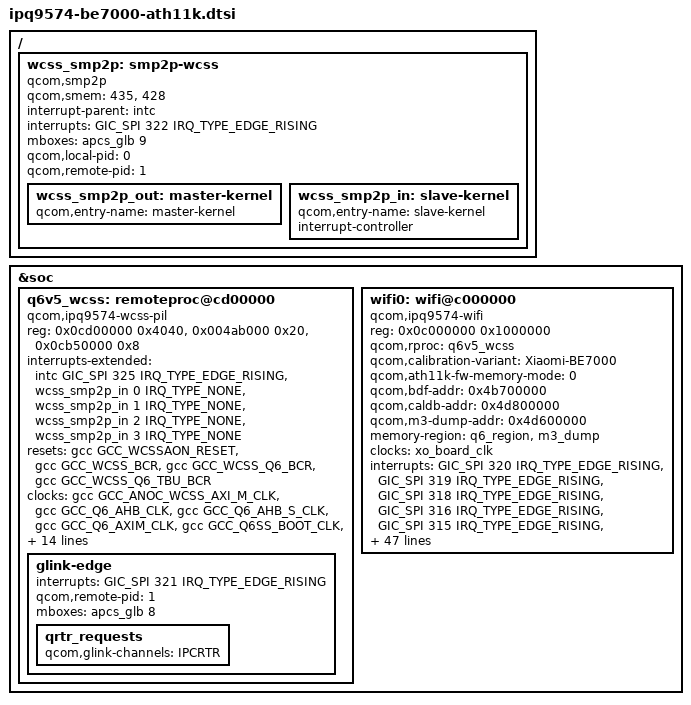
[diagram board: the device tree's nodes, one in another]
// SPDX-License-Identifier: (GPL-2.0+ OR BSD-3-Clause)
// Native WCSS/ath11k wiring, adapted from kravasuper/openwrt 790d036a178c.
/ {
	wcss_smp2p: smp2p-wcss {
		compatible = "qcom,smp2p";
		qcom,smem = <435>, <428>;
		interrupt-parent = <&intc>;
		interrupts = <GIC_SPI 322 IRQ_TYPE_EDGE_RISING>;
		mboxes = <&apcs_glb 9>;
		qcom,local-pid = <0>;
		qcom,remote-pid = <1>;

		wcss_smp2p_out: master-kernel {
			qcom,entry-name = "master-kernel";
			#qcom,smem-state-cells = <1>;
		};

		wcss_smp2p_in: slave-kernel {
			qcom,entry-name = "slave-kernel";
			interrupt-controller;
			#interrupt-cells = <2>;
		};
	};
};

&soc {
	q6v5_wcss: remoteproc@cd00000 {
		compatible = "qcom,ipq9574-wcss-pil";
		reg = <0x0cd00000 0x4040>,
		      <0x004ab000 0x20>,
		      <0x0cb50000 0x8>;
		reg-names = "qdsp6", "rmb", "wcmn";
		interrupts-extended = <&intc GIC_SPI 325 IRQ_TYPE_EDGE_RISING>,
				      <&wcss_smp2p_in 0 IRQ_TYPE_NONE>,
				      <&wcss_smp2p_in 1 IRQ_TYPE_NONE>,
				      <&wcss_smp2p_in 2 IRQ_TYPE_NONE>,
				      <&wcss_smp2p_in 3 IRQ_TYPE_NONE>;
		interrupt-names = "wdog",
				  "fatal",
				  "ready",
				  "handover",
				  "stop-ack";
		resets = <&gcc GCC_WCSSAON_RESET>,
			 <&gcc GCC_WCSS_BCR>,
			 <&gcc GCC_WCSS_Q6_BCR>,
			 <&gcc GCC_WCSS_Q6_TBU_BCR>;
		reset-names = "wcss_aon_reset",
			      "wcss_reset",
			      "wcss_q6_reset",
			      "wcss_q6_bcr_reset";
		clocks = <&gcc GCC_ANOC_WCSS_AXI_M_CLK>,
			 <&gcc GCC_Q6_AHB_CLK>,
			 <&gcc GCC_Q6_AHB_S_CLK>,
			 <&gcc GCC_Q6_AXIM_CLK>,
			 <&gcc GCC_Q6SS_BOOT_CLK>,
			 <&gcc GCC_MEM_NOC_Q6_AXI_CLK>,
			 <&gcc GCC_SYS_NOC_WCSS_AHB_CLK>,
			 <&gcc GCC_WCSS_ACMT_CLK>,
			 <&gcc GCC_WCSS_ECAHB_CLK>,
			 <&gcc GCC_WCSS_Q6_TBU_CLK>,
			 <&gcc GCC_Q6_AXIM2_CLK>,
			 <&gcc GCC_WCSS_AHB_S_CLK>,
			 <&gcc GCC_WCSS_AXI_M_CLK>;
		clock-names = "anoc_wcss_axi_m",
			      "q6_ahb",
			      "q6_ahb_s",
			      "q6_axim",
			      "q6ss_boot",
			      "mem_noc_q6_axi",
			      "sys_noc_wcss_ahb",
			      "wcss_acmt",
			      "wcss_ecahb",
			      "wcss_q6_tbu",
			      "q6_axim2",
			      "wcss_ahb_s",
			      "wcss_axi_m";
		qcom,halt-regs = <&tcsr 0x18000 0x1b000 0xe000>;
		qcom,smem-states = <&wcss_smp2p_out 0>,
				   <&wcss_smp2p_out 1>;
		qcom,smem-state-names = "shutdown",
					  "stop";
		memory-region = <&q6_region>, <&m3_dump>,
				<&q6_etr_region>, <&q6_caldb_region>;
		status = "okay";

		glink-edge {
			interrupts = <GIC_SPI 321 IRQ_TYPE_EDGE_RISING>;
			qcom,remote-pid = <1>;
			mboxes = <&apcs_glb 8>;

			qrtr_requests {
				qcom,glink-channels = "IPCRTR";
			};
		};
	};

	wifi0: wifi@c000000 {
		compatible = "qcom,ipq9574-wifi";
		reg = <0x0c000000 0x1000000>;
		qcom,rproc = <&q6v5_wcss>;
		qcom,calibration-variant = "Xiaomi-BE7000";
		qcom,ath11k-fw-memory-mode = <0>;
		qcom,bdf-addr = <0x4b700000>;
		qcom,caldb-addr = <0x4d800000>;
		qcom,m3-dump-addr = <0x4d600000>;
		memory-region = <&q6_region>, <&m3_dump>;
		clocks = <&xo_board_clk>;
		clock-names = "xo";
		interrupts = <GIC_SPI 320 IRQ_TYPE_EDGE_RISING>,
			     <GIC_SPI 319 IRQ_TYPE_EDGE_RISING>,
			     <GIC_SPI 318 IRQ_TYPE_EDGE_RISING>,
			     <GIC_SPI 316 IRQ_TYPE_EDGE_RISING>,
			     <GIC_SPI 315 IRQ_TYPE_EDGE_RISING>,
			     <GIC_SPI 314 IRQ_TYPE_EDGE_RISING>,
			     <GIC_SPI 311 IRQ_TYPE_EDGE_RISING>,
			     <GIC_SPI 310 IRQ_TYPE_EDGE_RISING>,
			     <GIC_SPI 411 IRQ_TYPE_EDGE_RISING>,
			     <GIC_SPI 410 IRQ_TYPE_EDGE_RISING>,
			     <GIC_SPI 40 IRQ_TYPE_EDGE_RISING>,
			     <GIC_SPI 39 IRQ_TYPE_EDGE_RISING>,
			     <GIC_SPI 302 IRQ_TYPE_EDGE_RISING>,
			     <GIC_SPI 301 IRQ_TYPE_EDGE_RISING>,
			     <GIC_SPI 37 IRQ_TYPE_EDGE_RISING>,
			     <GIC_SPI 36 IRQ_TYPE_EDGE_RISING>,
			     <GIC_SPI 296 IRQ_TYPE_EDGE_RISING>,
			     <GIC_SPI 295 IRQ_TYPE_EDGE_RISING>,
			     <GIC_SPI 294 IRQ_TYPE_EDGE_RISING>,
			     <GIC_SPI 293 IRQ_TYPE_EDGE_RISING>,
			     <GIC_SPI 292 IRQ_TYPE_EDGE_RISING>,
			     <GIC_SPI 291 IRQ_TYPE_EDGE_RISING>,
			     <GIC_SPI 290 IRQ_TYPE_EDGE_RISING>,
			     <GIC_SPI 289 IRQ_TYPE_EDGE_RISING>,
			     <GIC_SPI 288 IRQ_TYPE_EDGE_RISING>,
			     <GIC_SPI 239 IRQ_TYPE_EDGE_RISING>,
			     <GIC_SPI 236 IRQ_TYPE_EDGE_RISING>,
			     <GIC_SPI 235 IRQ_TYPE_EDGE_RISING>,
			     <GIC_SPI 234 IRQ_TYPE_EDGE_RISING>,
			     <GIC_SPI 233 IRQ_TYPE_EDGE_RISING>,
			     <GIC_SPI 232 IRQ_TYPE_EDGE_RISING>,
			     <GIC_SPI 231 IRQ_TYPE_EDGE_RISING>,
			     <GIC_SPI 230 IRQ_TYPE_EDGE_RISING>,
			     <GIC_SPI 229 IRQ_TYPE_EDGE_RISING>,
			     <GIC_SPI 228 IRQ_TYPE_EDGE_RISING>,
			     <GIC_SPI 224 IRQ_TYPE_EDGE_RISING>,
			     <GIC_SPI 223 IRQ_TYPE_EDGE_RISING>,
			     <GIC_SPI 203 IRQ_TYPE_EDGE_RISING>,
			     <GIC_SPI 183 IRQ_TYPE_EDGE_RISING>,
			     <GIC_SPI 180 IRQ_TYPE_EDGE_RISING>,
			     <GIC_SPI 179 IRQ_TYPE_EDGE_RISING>,
			     <GIC_SPI 178 IRQ_TYPE_EDGE_RISING>,
			     <GIC_SPI 177 IRQ_TYPE_EDGE_RISING>,
			     <GIC_SPI 176 IRQ_TYPE_EDGE_RISING>,
			     <GIC_SPI 163 IRQ_TYPE_EDGE_RISING>,
			     <GIC_SPI 162 IRQ_TYPE_EDGE_RISING>,
			     <GIC_SPI 160 IRQ_TYPE_EDGE_RISING>,
			     <GIC_SPI 414 IRQ_TYPE_EDGE_RISING>,
			     <GIC_SPI 159 IRQ_TYPE_EDGE_RISING>,
			     <GIC_SPI 158 IRQ_TYPE_EDGE_RISING>,
			     <GIC_SPI 157 IRQ_TYPE_EDGE_RISING>,
			     <GIC_SPI 156 IRQ_TYPE_EDGE_RISING>;
		interrupt-names = "misc-pulse1",
				  "misc-latch",
				  "sw-exception",
				  "ce0",
				  "ce1",
				  "ce2",
				  "ce3",
				  "ce4",
				  "ce5",
				  "ce6",
				  "ce7",
				  "ce8",
				  "ce9",
				  "ce10",
				  "ce11",
				  "host2wbm-desc-feed",
				  "host2reo-re-injection",
				  "host2reo-command",
				  "host2rxdma-monitor-ring3",
				  "host2rxdma-monitor-ring2",
				  "host2rxdma-monitor-ring1",
				  "reo2ost-exception",
				  "wbm2host-rx-release",
				  "reo2host-status",
				  "reo2host-destination-ring4",
				  "reo2host-destination-ring3",
				  "reo2host-destination-ring2",
				  "reo2host-destination-ring1",
				  "rxdma2host-monitor-destination-mac3",
				  "rxdma2host-monitor-destination-mac2",
				  "rxdma2host-monitor-destination-mac1",
				  "ppdu-end-interrupts-mac3",
				  "ppdu-end-interrupts-mac2",
				  "ppdu-end-interrupts-mac1",
				  "rxdma2host-monitor-status-ring-mac3",
				  "rxdma2host-monitor-status-ring-mac2",
				  "rxdma2host-monitor-status-ring-mac1",
				  "host2rxdma-host-buf-ring-mac3",
				  "host2rxdma-host-buf-ring-mac2",
				  "host2rxdma-host-buf-ring-mac1",
				  "rxdma2host-destination-ring-mac3",
				  "rxdma2host-destination-ring-mac2",
				  "rxdma2host-destination-ring-mac1",
				  "host2tcl-input-ring4",
				  "host2tcl-input-ring3",
				  "host2tcl-input-ring2",
				  "host2tcl-input-ring1",
				  "wbm2host-tx-completions-ring4",
				  "wbm2host-tx-completions-ring3",
				  "wbm2host-tx-completions-ring2",
				  "wbm2host-tx-completions-ring1",
				  "tcl2host-status-ring";
		status = "okay";
	};
};
